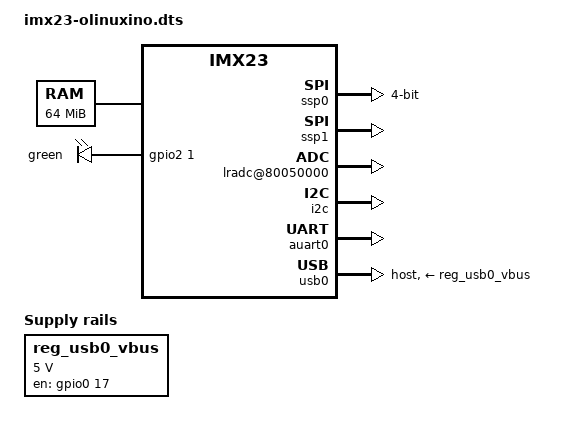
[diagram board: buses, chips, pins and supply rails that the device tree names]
/* bench 20224.0.0 a725c4066793 */
/* bench 20224.0.1 350a99809810 */
/* bench 20224.0.2 b6f48a4c3438 */
/* bench 20224.0.3 d87298a5167e */
/* bench 20224.0.4 0bed9006e939 */
/* bench 20224.0.5 9ff0759cefed */
/* bench 20224.0.6 f2c40534cb47 */
/* bench 20224.0.7 c9795cf86685 */
/* bench 20224.0.8 be4ae90ffba9 */
/* bench 20224.0.9 34e8bed3fb6e */
/* bench 20224.0.10 84264b8a2d95 */
/* bench 20224.0.11 0600e6d0523f */
/* bench 20224.0.12 5cb3771f3e5a */
 * Copyright 2012 Freescale Semiconductor, Inc.
 *
 * Author: Fabio Estevam <fabio.estevam@freescale.com>
 */

/dts-v1/;
#include <dt-bindings/gpio/gpio.h>
#include "imx23.dtsi"

/* bench 15113.0.0 94ada499665c */
/* bench 15113.0.1 d91ce4859382 */
/* bench 15113.0.2 f3019a95a284 */
/* bench 15113.0.3 816b1b18b8c0 */
/* bench 15113.0.4 64f2caf920e1 */
/* bench 15113.0.5 26f886ffd533 */
/* bench 15113.0.6 64fdf28815e9 */
/* bench 15113.0.7 15cdf62d27d0 */

	memory@40000000 {
		device_type = "memory";
		reg = <0x40000000 0x04000000>;
	};

	apb@80000000 {
		apbh@80000000 {
			ssp0: spi@80010000 {
				compatible = "fsl,imx23-mmc";
				pinctrl-names = "default";
				pinctrl-0 = <&mmc0_4bit_pins_a &mmc0_sck_cfg>;
				bus-width = <4>;
				broken-cd;
				status = "okay";
			};

			pinctrl@80018000 {
				pinctrl-names = "default";
				pinctrl-0 = <&hog_pins_a>;

				hog_pins_a: hog@0 {
					reg = <0>;
					fsl,pinmux-ids = <
						MX23_PAD_GPMI_ALE__GPIO_0_17
					>;
					fsl,drive-strength = <MXS_DRIVE_4mA>;
					fsl,voltage = <MXS_VOLTAGE_HIGH>;
					fsl,pull-up = <MXS_PULL_DISABLE>;
				};

				led_pin_gpio2_1: led_gpio2_1@0 {
					reg = <0>;
					fsl,pinmux-ids = <
						MX23_PAD_SSP1_DETECT__GPIO_2_1
					>;
					fsl,drive-strength = <MXS_DRIVE_4mA>;
					fsl,voltage = <MXS_VOLTAGE_HIGH>;
					fsl,pull-up = <MXS_PULL_DISABLE>;
				};
			};

			ssp1: spi@80034000 {
				#address-cells = <1>;
				#size-cells = <0>;
				compatible = "fsl,imx23-spi";
				pinctrl-names = "default";
				pinctrl-0 = <&spi2_pins_a>;
				status = "okay";
			};
		};

		apbx@80040000 {
			lradc@80050000 {
				status = "okay";
			};

			i2c: i2c@80058000 {
				pinctrl-names = "default";
				pinctrl-0 = <&i2c_pins_b>;
				status = "okay";
			};

			duart: serial@80070000 {
				pinctrl-names = "default";
				pinctrl-0 = <&duart_pins_a>;
/* bench 13026.0.0 26aa571068c1 */
/* bench 13026.0.1 d9819148479a */
/* bench 13026.0.2 2d4cb52ad857 */
/* bench 13026.0.3 4bb604ca9706 */
/* bench 13026.0.4 b512ac7879fb */
			};

			auart0: serial@8006c000 {
				pinctrl-names = "default";
				pinctrl-0 = <&auart0_2pins_a>;
				status = "okay";
			};

			usbphy0: usbphy@8007c000 {
				status = "okay";
			};
		};
	};

	ahb@80080000 {
		usb0: usb@80080000 {
			dr_mode = "host";
			vbus-supply = <&reg_usb0_vbus>;
			status = "okay";
		};
	};

	regulators {
		compatible = "simple-bus";
		#address-cells = <1>;
		#size-cells = <0>;

		reg_usb0_vbus: regulator@0 {
			compatible = "regulator-fixed";
			reg = <0>;
			regulator-name = "usb0_vbus";
			regulator-min-microvolt = <5000000>;
			regulator-max-microvolt = <5000000>;
			enable-active-high;
			startup-delay-us = <300>; /* LAN9215 requires a POR of 200us minimum */
			gpio = <&gpio0 17 0>;
		};
	};

	leds {
		compatible = "gpio-leds";
		pinctrl-names = "default";
		pinctrl-0 = <&led_pin_gpio2_1>;

		user {
			label = "green";
			gpios = <&gpio2 1 GPIO_ACTIVE_HIGH>;
		};
	};
};
/* bench 10742.1.0 dbc07cf97a8d */
/* bench 10742.1.1 704642105cfa */
/* bench 10742.1.2 1edfcd04e4e7 */
/* bench 10742.1.3 54cab1ede3e3 */
/* bench 10742.1.4 e614afa5680e */
/* bench 10742.1.5 dc06c091e699 */
/* bench 10742.1.6 bc8010122017 */
/* bench 10742.1.7 6db2dfc08bfa */
/* bench 10742.1.8 393cba05c728 */
/* bench 10742.1.9 93e5164c4f1e */
